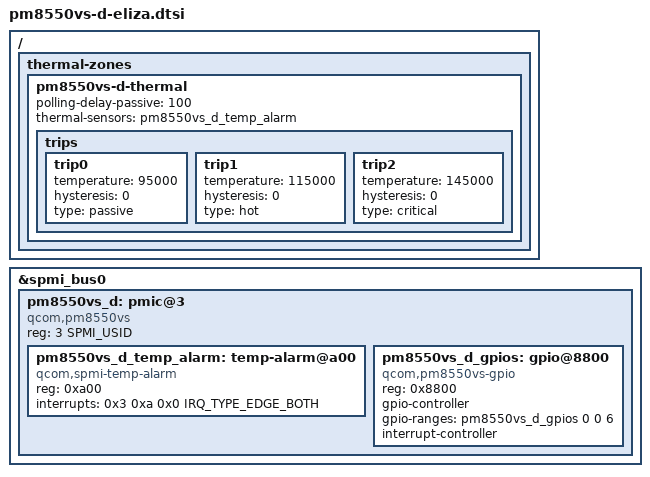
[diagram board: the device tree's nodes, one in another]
// SPDX-License-Identifier: BSD-3-Clause
/*
 * Copyright (c) 2026 Qualcomm Innovation Center, Inc. All rights reserved.
 */

#include <dt-bindings/interrupt-controller/irq.h>
#include <dt-bindings/spmi/spmi.h>

/ {
	thermal-zones {
		pm8550vs-d-thermal {
			polling-delay-passive = <100>;

			thermal-sensors = <&pm8550vs_d_temp_alarm>;

			trips {
				trip0 {
					temperature = <95000>;
					hysteresis = <0>;
					type = "passive";
				};

				trip1 {
					temperature = <115000>;
					hysteresis = <0>;
					type = "hot";
				};

				trip2 {
					temperature = <145000>;
					hysteresis = <0>;
					type = "critical";
				};
			};
		};
	};
};

&spmi_bus0 {
	pm8550vs_d: pmic@3 {
		compatible = "qcom,pm8550vs", "qcom,spmi-pmic";
		reg = <3 SPMI_USID>;
		#address-cells = <1>;
		#size-cells = <0>;

		pm8550vs_d_temp_alarm: temp-alarm@a00 {
			compatible = "qcom,spmi-temp-alarm";
			reg = <0xa00>;
			interrupts = <0x3 0xa 0x0 IRQ_TYPE_EDGE_BOTH>;
			#thermal-sensor-cells = <0>;
		};

		pm8550vs_d_gpios: gpio@8800 {
			compatible = "qcom,pm8550vs-gpio", "qcom,spmi-gpio";
			reg = <0x8800>;
			gpio-controller;
			gpio-ranges = <&pm8550vs_d_gpios 0 0 6>;
			#gpio-cells = <2>;
			interrupt-controller;
			#interrupt-cells = <2>;
		};
	};
};
